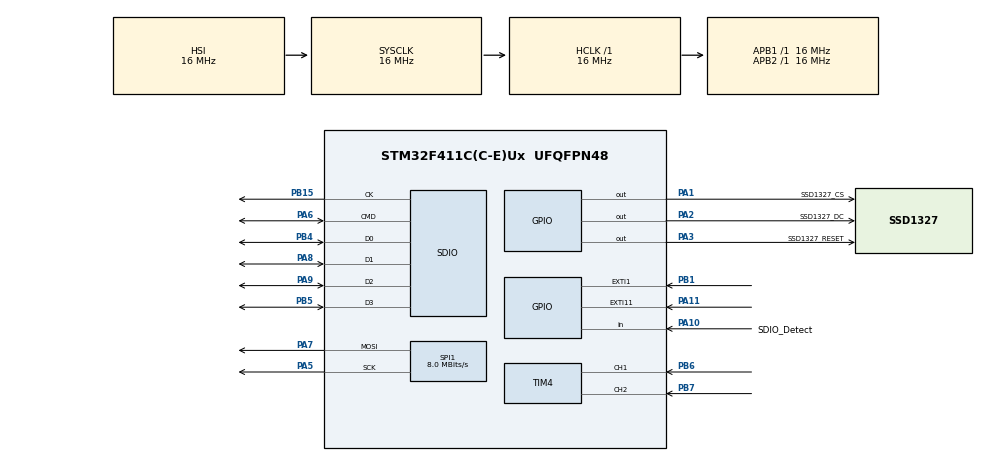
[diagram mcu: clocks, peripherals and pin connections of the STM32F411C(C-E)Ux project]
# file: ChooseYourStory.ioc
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Dma.Request0=SPI1_TX
Dma.SPI1_TX.0.Direction=DMA_MEMORY_TO_PERIPH
Dma.SPI1_TX.0.FIFOMode=DMA_FIFOMODE_DISABLE
Dma.SPI1_TX.0.Instance=DMA2_Stream2
Dma.SPI1_TX.0.MemDataAlignment=DMA_MDATAALIGN_BYTE
Dma.SPI1_TX.0.MemInc=DMA_MINC_ENABLE
Dma.SPI1_TX.0.Mode=DMA_NORMAL
Dma.SPI1_TX.0.PeriphDataAlignment=DMA_PDATAALIGN_BYTE
Dma.SPI1_TX.0.PeriphInc=DMA_PINC_DISABLE
Dma.SPI1_TX.0.Priority=DMA_PRIORITY_HIGH
FATFS.BSP.number=1
FATFS._USE_LFN=2
FATFS0.BSP.STBoard=false
FATFS0.BSP.api=Unknown
FATFS0.BSP.instance=PA10
FATFS0.BSP.ip=GPIO
FATFS0.BSP.mode=Input
FATFS0.BSP.name=Detect_SDIO
FATFS0.BSP.solution=PA10
Mcu.Family=STM32F4
Mcu.Name=STM32F411C(C-E)Ux
Mcu.Package=UFQFPN48
NVIC.DMA2_Stream2_IRQn=true\:0\:0\:false\:false\:true\:false\:true\:true
NVIC.EXTI15_10_IRQn=true\:0\:0\:false\:false\:true\:true\:true\:true
NVIC.PriorityGroup=NVIC_PRIORITYGROUP_4
PA1.GPIO_Label=SSD1327_CS
PA1.Signal=GPIO_Output
PA10.GPIO_Label=SDIO_Detect
PA10.Signal=GPIO_Input
PA11.GPIO_ModeDefaultEXTI=GPIO_MODE_IT_FALLING
PA11.GPIO_PuPd=GPIO_PULLUP
PA11.Signal=GPXTI11
PA2.GPIO_Label=SSD1327_DC
PA2.Signal=GPIO_Output
PA3.GPIO_Label=SSD1327_RESET
PA3.Signal=GPIO_Output
PA5.Mode=TX_Only_Simplex_Unidirect_Master
PA5.Signal=SPI1_SCK
PA6.Mode=SD_4_bits_Wide_bus
PA6.Signal=SDIO_CMD
PA7.Mode=TX_Only_Simplex_Unidirect_Master
PA7.Signal=SPI1_MOSI
PA8.Mode=SD_4_bits_Wide_bus
PA8.Signal=SDIO_D1
PA9.Mode=SD_4_bits_Wide_bus
PA9.Signal=SDIO_D2
PB1.GPIO_ModeDefaultEXTI=GPIO_MODE_IT_FALLING
PB1.GPIO_PuPd=GPIO_PULLUP
PB1.Signal=GPXTI1
PB15.Mode=SD_4_bits_Wide_bus
PB15.Signal=SDIO_CK
PB4.Mode=SD_4_bits_Wide_bus
PB4.Signal=SDIO_D0
PB5.Mode=SD_4_bits_Wide_bus
PB5.Signal=SDIO_D3
PB6.GPIO_PuPd=GPIO_PULLUP
PB6.GPIO_Speed=GPIO_SPEED_FREQ_LOW
PB6.Signal=S_TIM4_CH1
PB7.GPIO_PuPd=GPIO_PULLUP
PB7.GPIO_Speed=GPIO_SPEED_FREQ_LOW
PB7.Signal=S_TIM4_CH2
ProjectManager.HeapSize=0x200
ProjectManager.StackSize=0x400
ProjectManager.TargetToolchain=STM32CubeIDE
RCC.AHBFreq_Value=16000000
RCC.APB1Freq_Value=16000000
RCC.APB2Freq_Value=16000000
RCC.CortexFreq_Value=16000000
RCC.HSE_VALUE=25000000
RCC.HSI_VALUE=16000000
RCC.LSE_VALUE=32768
RCC.SYSCLKFreq_VALUE=16000000
RCC.VCOOutputFreq_Value=192000000
SH.S_TIM4_CH1.0=TIM4_CH1,Encoder_Interface
SH.S_TIM4_CH2.0=TIM4_CH2,Encoder_Interface
SPI1.BaudRatePrescaler=SPI_BAUDRATEPRESCALER_2
SPI1.CalculateBaudRate=8.0 MBits/s
SPI1.Direction=SPI_DIRECTION_2LINES
SPI1.Mode=SPI_MODE_MASTER
SPI1.VirtualType=VM_MASTER
TIM4.AutoReloadPreload=TIM_AUTORELOAD_PRELOAD_DISABLE
TIM4.EncoderMode=TIM_ENCODERMODE_TI12
TIM4.IC1Filter=15
TIM4.IC1Polarity=TIM_ICPOLARITY_FALLING
TIM4.IC2Filter=10
TIM4.IC2Polarity=TIM_ICPOLARITY_FALLING
TIM4.TIM_MasterOutputTrigger=TIM_TRGO_RESET
VP_FATFS_VS_SDIO.Mode=SDIO
board=custom

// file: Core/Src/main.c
/* USER CODE BEGIN Header */
/**
  ******************************************************************************
  * @file           : main.c
  * @brief          : Main program body
  ******************************************************************************
  * @attention
  *
  * Copyright (c) 2024 STMicroelectronics.
  * All rights reserved.
  *
  * This software is licensed under terms that can be found in the LICENSE file
  * in the root directory of this software component.
  * If no LICENSE file comes with this software, it is provided AS-IS.
  *
  ******************************************************************************
  */
/* USER CODE END Header */
#include "main.h"
#include "fatfs.h"

/* USER CODE BEGIN Includes */
#include "assets.h"
#include "game_handler.h"
/* USER CODE END Includes */

SD_HandleTypeDef hsd;

SPI_HandleTypeDef hspi1;
DMA_HandleTypeDef hdma_spi1_tx;

TIM_HandleTypeDef htim4;

void SystemClock_Config(void);
static void MX_GPIO_Init(void);
static void MX_DMA_Init(void);
static void MX_SPI1_Init(void);
static void MX_SDIO_SD_Init(void);
static void MX_TIM4_Init(void);

int main(void)
{

  /* MCU Configuration--------------------------------------------------------*/

  /* Reset of all peripherals, Initializes the Flash interface and the Systick. */
  HAL_Init();

  /* USER CODE BEGIN Init */
  Player plr;
  /* USER CODE END Init */

  /* Configure the system clock */
  SystemClock_Config();

  /* Initialize all configured peripherals */
  MX_GPIO_Init();
  MX_DMA_Init();
  MX_SPI1_Init();
  MX_SDIO_SD_Init();
  MX_TIM4_Init();
  MX_FATFS_Init();
  /* USER CODE BEGIN 2 */
  HAL_TIM_Encoder_Start_IT(&htim4, TIM_CHANNEL_ALL);
  TIM4->SR = 0;
  gameInit(&hspi1, &htim4,&plr);
  /* USER CODE END 2 */

  /* Infinite loop */
  while (1)
  {

  }
}

void SystemClock_Config(void)
{
  RCC_OscInitTypeDef RCC_OscInitStruct = {0};
  RCC_ClkInitTypeDef RCC_ClkInitStruct = {0};

  /** Configure the main internal regulator output voltage
  */
  __HAL_RCC_PWR_CLK_ENABLE();
  __HAL_PWR_VOLTAGESCALING_CONFIG(PWR_REGULATOR_VOLTAGE_SCALE1);

  /** Initializes the RCC Oscillators according to the specified parameters
  * in the RCC_OscInitTypeDef structure.
  */
  RCC_OscInitStruct.OscillatorType = RCC_OSCILLATORTYPE_HSI;
  RCC_OscInitStruct.HSIState = RCC_HSI_ON;
  RCC_OscInitStruct.HSICalibrationValue = RCC_HSICALIBRATION_DEFAULT;
  RCC_OscInitStruct.PLL.PLLState = RCC_PLL_ON;
  RCC_OscInitStruct.PLL.PLLSource = RCC_PLLSOURCE_HSI;
  RCC_OscInitStruct.PLL.PLLM = 16;
  RCC_OscInitStruct.PLL.PLLN = 192;
  RCC_OscInitStruct.PLL.PLLP = RCC_PLLP_DIV2;
  RCC_OscInitStruct.PLL.PLLQ = 4;
  if (HAL_RCC_OscConfig(&RCC_OscInitStruct) != HAL_OK)
  {
    Error_Handler();
  }

  /** Initializes the CPU, AHB and APB buses clocks
  */
  RCC_ClkInitStruct.ClockType = RCC_CLOCKTYPE_HCLK|RCC_CLOCKTYPE_SYSCLK
                              |RCC_CLOCKTYPE_PCLK1|RCC_CLOCKTYPE_PCLK2;
  RCC_ClkInitStruct.SYSCLKSource = RCC_SYSCLKSOURCE_HSI;
  RCC_ClkInitStruct.AHBCLKDivider = RCC_SYSCLK_DIV1;
  RCC_ClkInitStruct.APB1CLKDivider = RCC_HCLK_DIV1;
  RCC_ClkInitStruct.APB2CLKDivider = RCC_HCLK_DIV1;

  if (HAL_RCC_ClockConfig(&RCC_ClkInitStruct, FLASH_LATENCY_0) != HAL_OK)
  {
    Error_Handler();
  }
}

static void MX_SDIO_SD_Init(void)
{

  hsd.Instance = SDIO;
  hsd.Init.ClockEdge = SDIO_CLOCK_EDGE_RISING;
  hsd.Init.ClockBypass = SDIO_CLOCK_BYPASS_DISABLE;
  hsd.Init.ClockPowerSave = SDIO_CLOCK_POWER_SAVE_DISABLE;
  hsd.Init.BusWide = SDIO_BUS_WIDE_4B;
  hsd.Init.HardwareFlowControl = SDIO_HARDWARE_FLOW_CONTROL_DISABLE;
  hsd.Init.ClockDiv = 0;

}

static void MX_SPI1_Init(void)
{

  /* SPI1 parameter configuration*/
  hspi1.Instance = SPI1;
  hspi1.Init.Mode = SPI_MODE_MASTER;
  hspi1.Init.Direction = SPI_DIRECTION_2LINES;
  hspi1.Init.DataSize = SPI_DATASIZE_8BIT;
  hspi1.Init.CLKPolarity = SPI_POLARITY_LOW;
  hspi1.Init.CLKPhase = SPI_PHASE_1EDGE;
  hspi1.Init.NSS = SPI_NSS_SOFT;
  hspi1.Init.BaudRatePrescaler = SPI_BAUDRATEPRESCALER_2;
  hspi1.Init.FirstBit = SPI_FIRSTBIT_MSB;
  hspi1.Init.TIMode = SPI_TIMODE_DISABLE;
  hspi1.Init.CRCCalculation = SPI_CRCCALCULATION_DISABLE;
  hspi1.Init.CRCPolynomial = 10;
  if (HAL_SPI_Init(&hspi1) != HAL_OK)
  {
    Error_Handler();
  }

}

static void MX_TIM4_Init(void)
{

  TIM_Encoder_InitTypeDef sConfig = {0};
  TIM_MasterConfigTypeDef sMasterConfig = {0};

  htim4.Instance = TIM4;
  htim4.Init.Prescaler = 0;
  htim4.Init.CounterMode = TIM_COUNTERMODE_UP;
  htim4.Init.Period = 65535;
  htim4.Init.ClockDivision = TIM_CLOCKDIVISION_DIV1;
  htim4.Init.AutoReloadPreload = TIM_AUTORELOAD_PRELOAD_DISABLE;
  sConfig.EncoderMode = TIM_ENCODERMODE_TI12;
  sConfig.IC1Polarity = TIM_ICPOLARITY_FALLING;
  sConfig.IC1Selection = TIM_ICSELECTION_DIRECTTI;
  sConfig.IC1Prescaler = TIM_ICPSC_DIV1;
  sConfig.IC1Filter = 15;
  sConfig.IC2Polarity = TIM_ICPOLARITY_FALLING;
  sConfig.IC2Selection = TIM_ICSELECTION_DIRECTTI;
  sConfig.IC2Prescaler = TIM_ICPSC_DIV1;
  sConfig.IC2Filter = 10;
  if (HAL_TIM_Encoder_Init(&htim4, &sConfig) != HAL_OK)
  {
    Error_Handler();
  }
  sMasterConfig.MasterOutputTrigger = TIM_TRGO_RESET;
  sMasterConfig.MasterSlaveMode = TIM_MASTERSLAVEMODE_DISABLE;
  if (HAL_TIMEx_MasterConfigSynchronization(&htim4, &sMasterConfig) != HAL_OK)
  {
    Error_Handler();
  }

}

static void MX_DMA_Init(void)
{

  /* DMA controller clock enable */
  __HAL_RCC_DMA2_CLK_ENABLE();

  /* DMA interrupt init */
  /* DMA2_Stream2_IRQn interrupt configuration */
  HAL_NVIC_SetPriority(DMA2_Stream2_IRQn, 0, 0);
  HAL_NVIC_EnableIRQ(DMA2_Stream2_IRQn);

}

static void MX_GPIO_Init(void)
{
  GPIO_InitTypeDef GPIO_InitStruct = {0};

  /* GPIO Ports Clock Enable */
  __HAL_RCC_GPIOA_CLK_ENABLE();
  __HAL_RCC_GPIOB_CLK_ENABLE();

  /*Configure GPIO pin Output Level */
  HAL_GPIO_WritePin(GPIOA, SSD1327_CS_Pin|SSD1327_DC_Pin|SSD1327_RESET_Pin, GPIO_PIN_RESET);

  /*Configure GPIO pins : SSD1327_CS_Pin SSD1327_DC_Pin SSD1327_RESET_Pin */
  GPIO_InitStruct.Pin = SSD1327_CS_Pin|SSD1327_DC_Pin|SSD1327_RESET_Pin;
  GPIO_InitStruct.Mode = GPIO_MODE_OUTPUT_PP;
  GPIO_InitStruct.Pull = GPIO_NOPULL;
  GPIO_InitStruct.Speed = GPIO_SPEED_FREQ_LOW;
  HAL_GPIO_Init(GPIOA, &GPIO_InitStruct);

  /*Configure GPIO pin : PB1 */
  GPIO_InitStruct.Pin = GPIO_PIN_1;
  GPIO_InitStruct.Mode = GPIO_MODE_IT_FALLING;
  GPIO_InitStruct.Pull = GPIO_PULLUP;
  HAL_GPIO_Init(GPIOB, &GPIO_InitStruct);

  /*Configure GPIO pin : SDIO_Detect_Pin */
  GPIO_InitStruct.Pin = SDIO_Detect_Pin;
  GPIO_InitStruct.Mode = GPIO_MODE_INPUT;
  GPIO_InitStruct.Pull = GPIO_NOPULL;
  HAL_GPIO_Init(SDIO_Detect_GPIO_Port, &GPIO_InitStruct);

  /*Configure GPIO pin : PA11 */
  GPIO_InitStruct.Pin = GPIO_PIN_11;
  GPIO_InitStruct.Mode = GPIO_MODE_IT_FALLING;
  GPIO_InitStruct.Pull = GPIO_PULLUP;
  HAL_GPIO_Init(GPIOA, &GPIO_InitStruct);

  /* EXTI interrupt init*/
  HAL_NVIC_SetPriority(EXTI15_10_IRQn, 0, 0);
  HAL_NVIC_EnableIRQ(EXTI15_10_IRQn);

}

/* USER CODE BEGIN 4 */
void HAL_GPIO_EXTI_Callback(uint16_t GPIO_Pin){
	if (GPIO_Pin == GPIO_PIN_11){
		playerSelectOption = 0x01;
	} else if(GPIO_Pin == GPIO_PIN_1){
	}
}

/* USER CODE END 4 */

void Error_Handler(void)
{
  __disable_irq();
  while (1)
  {
  }
}
